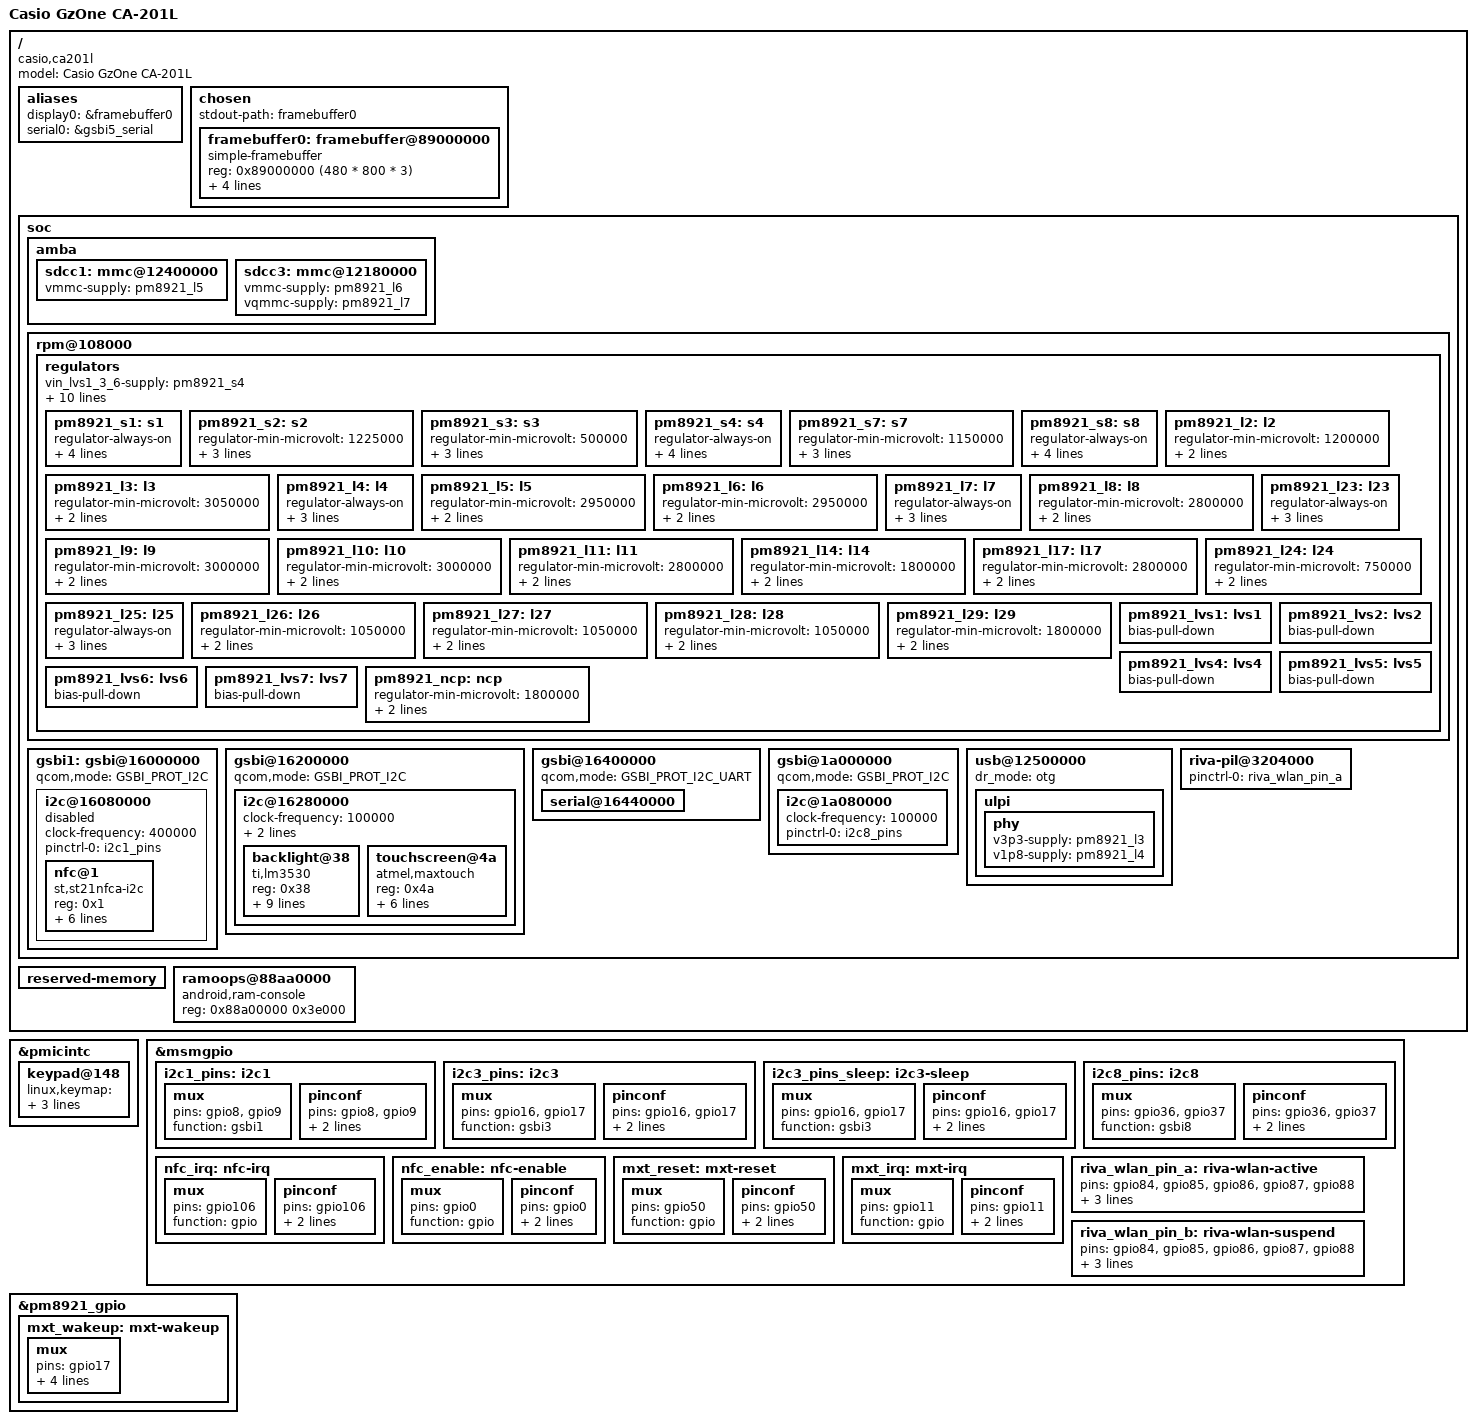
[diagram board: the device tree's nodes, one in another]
// SPDX-License-Identifier: GPL-2.0
#include <dt-bindings/input/input.h>
#include <dt-bindings/input/atmel-maxtouch.h>
#include <dt-bindings/gpio/gpio.h>
#include <dt-bindings/pinctrl/qcom,pmic-gpio.h>

#include "qcom-msm8960.dtsi"

/ {
	model = "Casio GzOne CA-201L";
	compatible = "casio,ca201l", "qcom,msm8960";

	aliases {
		display0 = &framebuffer0;
		serial0 = &gsbi5_serial;
	};

	chosen {
		stdout-path = "framebuffer0";

		#address-cells = <1>;
		#size-cells = <1>;
		ranges;

		framebuffer0: framebuffer@89000000 {
			compatible = "simple-framebuffer";
			reg = <0x89000000 (480 * 800 * 3)>;
			width = <480>;
			height = <800>;
			stride = <(480 * 3)>;
			//format = "b8g8r8";
			format = "r8g8b8";
		};
	};


	soc {
		amba {
		 	/* eMMC */
			sdcc1: mmc@12400000 {
				status = "okay";
				vmmc-supply = <&pm8921_l5>;
			};

		 	/* External micro SD card */
			sdcc3: mmc@12180000 {
				status = "okay";
				vmmc-supply = <&pm8921_l6>;
				vqmmc-supply = <&pm8921_l7>;
			};
		};

		rpm@108000 {
			regulators {
				vin_lvs1_3_6-supply = <&pm8921_s4>;
				vin_lvs2-supply = <&pm8921_s1>;
				vin_lvs4_5_7-supply = <&pm8921_s4>;
				vdd_ncp-supply = <&pm8921_l6>;
				vdd_l1_l2_l12_l18-supply = <&pm8921_s4>;
				vdd_l21_l23_l29-supply = <&pm8921_s8>;
				vdd_l24-supply = <&pm8921_s1>;
				vdd_l25-supply = <&pm8921_s1>;
				vdd_l26-supply = <&pm8921_s7>;
				vdd_l27-supply = <&pm8921_s7>;
				vdd_l28-supply = <&pm8921_s7>;

				/* Buck SMPS */
				/* lvs2 supply */
				pm8921_s1: s1 {
					regulator-always-on;
					regulator-min-microvolt = <1225000>;
					regulator-max-microvolt = <1225000>;
					qcom,switch-mode-frequency = <3200000>;
					bias-pull-down;
				};

				/* s2: iris_vddrfa (wcnss_wlan.0) */
				/* changed-min-microvolt -> 1225000 */
				/* changed-max-microvolt -> 1225000 */
				pm8921_s2: s2 {
					regulator-min-microvolt = <1225000>;
					regulator-max-microvolt = <1225000>;
					qcom,switch-mode-frequency = <1600000>;
					bias-pull-down;
				};

				/* s3: hsusb_vddcx (msm_otg), riva_vddcx (wcnss_wlan.0),
				   hsic_vddcx (msm_hsic_host) */
				pm8921_s3: s3 {
					regulator-min-microvolt = <500000>;
					regulator-max-microvolt = <1150000>;
					qcom,switch-mode-frequency = <4800000>;
					bias-pull-down;
				};

				/* s4: sdc_vdd_io (msm_sdcc.1), sdc_vdd (msm_sdcc.2),
				   sdc_vdd_io (msm_sdcc.4), riva_vddpx (wcnss_wlan.0),
				   hdmi_vcc (hdmi_msm.0), vddio_cdc, cdc_vdd_cp, cdc_vdda_tx,
				   cdc_vdda_rx (tabla-slim), vddio_cdc, cdc_vdd_cp,
				   cdc_vdda_tx, cdc_vdda_rx (tabla2x-slim), vcc_i2c (3-005b),
				   ext_hub_vddio (msm_hsic_host), vcc_i2c (10-0048) */
				pm8921_s4: s4 {
					regulator-always-on;
					regulator-min-microvolt = <1800000>;
					regulator-max-microvolt = <1800000>;
					qcom,switch-mode-frequency = <1600000>;
					bias-pull-down;
				};
			
				/* s5: krait0 */

				/* s6: krait1 */

				/* l28 supply */
				pm8921_s7: s7 {
					regulator-min-microvolt = <1150000>;
					regulator-max-microvolt = <1150000>;
					qcom,switch-mode-frequency = <3200000>;
					bias-pull-down;
				};

				/* l21, l23, l29 supply */
				pm8921_s8: s8 {
					regulator-always-on;
					regulator-min-microvolt = <2050000>;
					regulator-max-microvolt = <2050000>;
					qcom,switch-mode-frequency = <1600000>;
					bias-pull-down;
				};

				/* PMOS LDO */
				/* No consumers defined in downstream kernel */
				// pm8921_l1: l1 {
				// 	regulator-always-on;
				// 	regulator-min-microvolt = <1050000>;
				// 	regulator-max-microvolt = <1050000>;
				// 	bias-pull-down;
				// };

				/* l2: dsi_vdda (mipi_dsi.1), mipi_csi_vdd (msm_csid.[012]) */
				pm8921_l2: l2 {
					regulator-min-microvolt = <1200000>;
					regulator-max-microvolt = <1200000>;
					bias-pull-down;
				};

				/* l3: HSUSB_3p3 (msm_otg), voltage from drivers */
				/* changed-min-microvolt -> 3050000 */
				/* changed-max-microvolt -> 3300000 */
				pm8921_l3: l3 {
					regulator-min-microvolt = <3050000>;
					regulator-max-microvolt = <3300000>;
					bias-pull-down;
				};

				/* l4: HSUSB_1p8 (msm_otg), iris_vddxo (wcnss_wlan.0) */
				pm8921_l4: l4 {
					regulator-always-on;
					regulator-min-microvolt = <1800000>;
					regulator-max-microvolt = <1800000>;
					bias-pull-down;
				};

				/* l5: sdc_vdd (msm_sdcc.1) */
				pm8921_l5: l5 {
					regulator-min-microvolt = <2950000>;
					regulator-max-microvolt = <2950000>;
					bias-pull-down;
				};

				/* l6: sdc_vdd (msm_sdcc.3) */
				pm8921_l6: l6 {
					regulator-min-microvolt = <2950000>;
					regulator-max-microvolt = <2950000>;
					bias-pull-down;
				};

				/* l7: sdc_vdd_io (msm_sdcc.3) */
				pm8921_l7: l7 {
					regulator-always-on;
					regulator-min-microvolt = <1850000>;
					regulator-max-microvolt = <2950000>;
					bias-pull-down;
				};

				/* l8: dsi_vdc (mipi_dsi.1) */
				/* changed-max-microvolt -> 2800000 */
				pm8921_l8: l8 {
					regulator-min-microvolt = <2800000>;
					regulator-max-microvolt = <2800000>;
					bias-pull-down;
				};

				/* l9: vdd (3-0024), vdd_ana (3-004a), sensor_vdd (msm_dsps) */
				pm8921_l9: l9 {
					regulator-min-microvolt = <3000000>;
					regulator-max-microvolt = <3000000>;
					bias-pull-down;
				};

				/* l10: iris_vddpa (wcnss_wlan.0) */
				pm8921_l10: l10 {
					regulator-min-microvolt = <3000000>;
					regulator-max-microvolt = <3000000>;
					bias-pull-down;
				};

				/* l11: cam_vana (4-003c, 4-001a, 4-006c, 4-0048, 4-0020, 4-0034, 4-0036) */
				/* changed-min-microvolt -> 2800000 */
				/* changed-max-microvolt -> 2800000 */
				pm8921_l11: l11 {
					regulator-min-microvolt = <2800000>;
					regulator-max-microvolt = <2800000>;
					bias-pull-down;
				};

				/* No consumers defined in downstream kernel */
				// pm8921_l12: l12 {
				// 	regulator-min-microvolt = <1200000>;
				// 	regulator-max-microvolt = <1200000>;
				// 	bias-pull-down;
				// };

				/* l14: pa_therm (pm8xxx-adc) */
				pm8921_l14: l14 {
					regulator-min-microvolt = <1800000>;
					regulator-max-microvolt = <1800000>;
					bias-pull-down;
				};

				/* No consumers defined in downstream kernel */
				// pm8921_l15: l15 {
				// 	regulator-min-microvolt = <1800000>;
				// 	regulator-max-microvolt = <2950000>;
				// 	bias-pull-down;
				// };

				/* No consumers defined in downstream kernel */
				// pm8921_l16: l16 {
				// 	regulator-min-microvolt = <2800000>;
				// 	regulator-max-microvolt = <2800000>;
				// 	bias-pull-down;
				// };

				/* l17: cam_vdig (4-0036, 4-003c) */
				/* changed-min-microvolt -> 2800000 */
				/* changed-max-microvolt -> 2800000 */
				pm8921_l17: l17 {
					regulator-min-microvolt = <2800000>;
					regulator-max-microvolt = <2800000>;
					bias-pull-down;
				};

				/* No consumers defined in downstream kernel */
				// pm8921_l18: l18 {
				// 	regulator-min-microvolt = <1300000>;
				// 	regulator-max-microvolt = <1300000>;
				// 	bias-pull-down;
				// };

				/* No consumers defined in downstream kernel */
				// pm8921_l21: l21 {
				// 	regulator-min-microvolt = <1900000>;
				// 	regulator-max-microvolt = <1900000>;
				// 	bias-pull-down;
				// };

				/* No consumers defined in downstream kernel */
				// pm8921_l22: l22 {
				// 	regulator-min-microvolt = <2750000>;
				// 	regulator-max-microvolt = <2750000>;
				// 	bias-pull-down;
				// };

				/* l23: dsi_vddio (mipi_dsi.1), hdmi_avdd (hdmi_msm.0),
				   hdmi_pll_fs (mdp.0), pll_vdd (pil_riva, pil_qdsp6v4.[12]) */
				pm8921_l23: l23 {
					regulator-always-on;
					regulator-min-microvolt = <1800000>;
					regulator-max-microvolt = <1800000>;
					bias-pull-down;
				};

				/* l24: riva_vddmx (wcnss_wlan.0) */
				pm8921_l24: l24 {
					regulator-min-microvolt = <750000>;
					regulator-max-microvolt = <1150000>;
					bias-pull-down;
				};

				/* l25:vddd_cdc_d, cdc_vdda_a_1p2v (tabla-slim),
				   vddd_cdc_d, cdc_vdda_a_1p2v (tabla2x-slim) */
				pm8921_l25: l25 {
					regulator-always-on;
					regulator-min-microvolt = <1250000>;
					regulator-max-microvolt = <1250000>;
					bias-pull-down;
				};

				/* l26: core_vdd (pil_qdsp6v4.0) */
				pm8921_l26: l26 {
					regulator-min-microvolt = <1050000>;
					regulator-max-microvolt = <1050000>;
					bias-pull-down;
				};

				/* l27: core_vdd (pil_qdsp6v4.2) */
				pm8921_l27: l27 {
					regulator-min-microvolt = <1050000>;
					regulator-max-microvolt = <1050000>;
					bias-pull-down;
				};

				/* l28: core_vdd (pil_qdsp6v4.1) */
				pm8921_l28: l28 {
					regulator-min-microvolt = <1050000>;
					regulator-max-microvolt = <1050000>;
					bias-pull-down;
				};

				/* l29: touch_io */
				/* changed-min-microvolt -> 1800000 */
				/* changed-max-microvolt -> 1800000 */
				pm8921_l29: l29 {
					regulator-min-microvolt = <1800000>;
					regulator-max-microvolt = <1800000>;
					bias-pull-down;
				};

				/* Low Voltage Switch */
				/* lvs1: iris_vddio (wcnss_wlan.0) */
				pm8921_lvs1: lvs1 {
					bias-pull-down;
				};

				/* lvs2: iris_vdddig (wcnss_wlan.0) */
				pm8921_lvs2: lvs2 {
					bias-pull-down;
				};

				/* No consumers defined in downstream kernel */
				// pm8921_lvs3: lvs3 {
				// 	bias-pull-down;
				// };

				/* lvs4: vcc_i2c (3-0024, 3-004a), sensor_vddio (msm_dsps) */
				pm8921_lvs4: lvs4 {
					bias-pull-down;
				};

				/* lvs5: cam_vio (4-003c, 4-001a, 4-006c, 4-0048, 4-0020, 4-0036) */
				pm8921_lvs5: lvs5 {
					bias-pull-down;
				};

				/* lvs6: vdd_io (spi0.0) */
				/* No SPI devices are defined */
				pm8921_lvs6: lvs6 {
					bias-pull-down;
				};

				/* No consumers defined in downstream kernel */
				pm8921_lvs7: lvs7 {
					bias-pull-down;
				};

				/* No consumers defined in downstream kernel */
				pm8921_ncp: ncp {
					regulator-min-microvolt = <1800000>;
					regulator-max-microvolt = <1800000>;
					qcom,switch-mode-frequency = <1600000>;
				};
			};
		};

		/* gsbi1: i2c - st21nfca, GPIO: 8, 9, 106 (ST21NFCA_WAKEUP) */
		gsbi1: gsbi@16000000 {
			status = "okay";
			qcom,mode = <GSBI_PROT_I2C>;

			i2c@16080000 {
				status = "disabled";
				clock-frequency = <400000>;
				pinctrl-0 = <&i2c1_pins>;
				pinctrl-names = "default";

				/* 1-0001: st21nfca */
				/* st21nfca_probe : IRQ GPIO is 106
				   st21nfca_probe : ENA GPIO is 0
				   st21nfca_probe : IRQ_TYPE is 2, active_polarity is 0
				*/
				nfc@1 {
					compatible = "st,st21nfca-i2c";
					reg = <0x1>;

					pinctrl-names = "default";
					pinctrl-0 = <&nfc_irq>, <&nfc_enable>;
					interrupt-parent = <&msmgpio>;
					interrupts = <106 IRQ_TYPE_EDGE_FALLING>;
					enable-gpios = <&msmgpio 0 GPIO_ACTIVE_HIGH>;

					ese-present;
					uicc-present;
				};
			};
		};

		/* gsbi3: i2c - mxt224e, backlight (rev3, rev >= 8), GPIO: 16 (SDA), 17 (SCL) */
		gsbi@16200000 {
			status = "okay";
			qcom,mode = <GSBI_PROT_I2C>;

			i2c@16280000 {
				status = "okay";
				clock-frequency = <100000>;
				pinctrl-0 = <&i2c3_pins>;
				pinctrl-1 = <&i2c3_pins_sleep>;
				pinctrl-names = "default", "sleep";

				/* 3-0038: lm3530 */
				backlight@38 {
					status = "okay";
					compatible = "ti,lm3530";
					reg = <0x38>;

					enable-gpios = <&pm8921_gpio 24 GPIO_ACTIVE_HIGH>;
					default-brightness = /bits/ 8 <0x33>;
					max-brightness = /bits/ 8 <0x7f>;
					ramp-up-ms = <128>;
					ramp-down-ms = <128>;
					ti,current-limit = /bits/ 8 <0x05>; // 22.5 mA, bit 4 to 2 of 0x10
					ti,led-mode = /bits/ 8 <0x00>; /* Manual mode */
					ti,linear-mapping-mode = /bits/ 8 <1>; /* Linear map */
					ti,no-regulator;
				};

				/* 3-004a: mXT224E */
				/* power on: GPIO 50 -> 1, power off: GPIO 50 -> 0
				   TOUCH_RESET_GPIO 50 -> direction output, 1
				   MXT224E_TS_GPIO_IRQ 11 -> direction input
				   MXT224E_TS_VDD 17 -> PM8921_GPIO_PM_TO_SYS
				*/
				touchscreen@4a {
					compatible = "atmel,maxtouch";
					reg = <0x4a>;

					pinctrl-names = "default";
					pinctrl-0 = <&mxt_irq>, <&mxt_reset>, <&mxt_wakeup>;
					interrupt-parent = <&msmgpio>;
					interrupts = <11 IRQ_TYPE_LEVEL_LOW>;
					reset-gpios = <&msmgpio 50 GPIO_ACTIVE_LOW>;
					atmel,wakeup-method = <ATMEL_MXT_WAKEUP_GPIO>;
					wake-gpios = <&pm8921_gpio 17 GPIO_ACTIVE_HIGH>;
				};
			};
		};

		/* gsbi4: i2c - camera main, camera sub */
		// mt9m113, mt9e013 - no drivers
		// gsbi@16300000 {
		// 	status = "okay";
		// 	qcom,mode = <GSBI_PROT_I2C>;

		// 	i2c@16380000 {
		// 		status = "okay";
		// 		clock-frequency = <360000>;
		// 		pinctrl-0 = <&i2c4_pins>;
		// 		pinctrl-names = "default";
		// 	};
		// };

		/* gsbi5: uart (GPIO: 22, 23, 24, 25) */
		gsbi@16400000 {
			status = "okay";
			qcom,mode = <GSBI_PROT_I2C_UART>;
			serial@16440000 {
				status = "okay";
			};
		};

		/* gsbi8: i2c - yda160, es310 (GPIO: 36, 37) */
		// es310, yda160 - no drivers
		gsbi@1a000000 {
			status = "okay";
			qcom,mode = <GSBI_PROT_I2C>;

			i2c@1a080000 {
				status = "okay";
				clock-frequency = <100000>;
				pinctrl-0 = <&i2c8_pins>;
				pinctrl-names = "default";
			};
		};

		usb@12500000 {
			status = "okay";
			dr_mode = "otg";

			ulpi {
				phy {
					v3p3-supply = <&pm8921_l3>;
					v1p8-supply = <&pm8921_l4>;
				};
			};
		};

		riva-pil@3204000 {
			status = "okay";

			pinctrl-names = "default";
			pinctrl-0 = <&riva_wlan_pin_a>; //, <&riva_bt_pin_a>, <&riva_fm_pin_a>;
		};
	};

	reserved-memory {
		#address-cells = <1>;
		#size-cells = <1>;
		ranges;

		// framebuffer_region@89000000 {
		// 	reg = <0x89000000 (480 * 800 * 3)>;
		// 	no-map;
		// };
	};

	ramoops@88aa0000 {
		// compatible = "ramoops";
		compatible = "android,ram-console";
		reg = <0x88a00000 0x3e000>;
		// console-size = <0x3e000>;
		// record-size = <0x3e000>;
		// ftrace-size = <0x0>;
		// pmsg-size = <0x3e000>;
		// ecc-size = <0x10>;
	};

};

&pmicintc {
	keypad@148 {
		// KEY_TACTILE: only existing in this device
		linux,keymap = <
			MATRIX_KEY(0, 0, KEY_HOME)
			MATRIX_KEY(0, 1, KEY_VOLUMEUP)
			MATRIX_KEY(0, 2, KEY_VOLUMEDOWN)
			>;
		keypad,num-rows = <1>;
		keypad,num-columns = <5>;
	};
};

&msmgpio {
	i2c1_pins: i2c1 {
		mux {
			pins = "gpio8", "gpio9";
			function = "gsbi1";
		};

		pinconf {
			pins = "gpio8", "gpio9";
			drive-strength = <8>;
			bias-disable;
		};
	};

	i2c3_pins: i2c3 {
		mux {
			pins = "gpio16", "gpio17";
			function = "gsbi3";
		};

		pinconf {
			pins = "gpio16", "gpio17";
			drive-strength = <8>;
			bias-disable;
		};
	};

	i2c3_pins_sleep: i2c3-sleep {
		mux {
			pins = "gpio16", "gpio17";
			function = "gsbi3";
		};

		pinconf {
			pins = "gpio16", "gpio17";
			drive-strength = <2>;
			bias-disable;
		};
	};

	i2c8_pins: i2c8 {
		mux {
			pins = "gpio36", "gpio37";
			function = "gsbi8";
		};

		pinconf {
			pins = "gpio36", "gpio37";
			drive-strength = <8>;
			bias-disable;
		};
	};

	nfc_irq: nfc-irq {
		mux {
			pins = "gpio106";
			function = "gpio";
		};

		pinconf {
			pins = "gpio106";
			drive-strengh = <2>;
			bias-disable;
		};
	};

	nfc_enable: nfc-enable {
		mux {
			pins = "gpio0";
			function = "gpio";
		};

		pinconf {
			pins = "gpio0";
			drive-strengh = <2>;
			bias-disable;
		};
	};

	mxt_reset: mxt-reset {
		mux {
			pins = "gpio50";
			function = "gpio";
		};

		pinconf {
			pins = "gpio50";
			drive-strength = <6>;
			bias-pull-up;
		};
	};

	mxt_irq: mxt-irq {
		mux {
			pins = "gpio11";
			function = "gpio";
		};

		pinconf {
			pins = "gpio11";
			drive-strength = <8>;
			bias-pull-up;
		};
	};

	// riva_fm_pin_a: riva-fm-active {
	// 	pins = "gpio14", "gpio15";
	// 	function = "riva_fm";
	// };

	// riva_bt_pin_a: riva-bt-active {
	// 	pins = "gpio16", "gpio17";
	// 	function = "riva_bt";
	// };

	riva_wlan_pin_a: riva-wlan-active {
		pins = "gpio84", "gpio85", "gpio86", "gpio87", "gpio88";
		function = "wlan";

		drive-strength = <6>;
		bias-pull-down;
	};

	riva_wlan_pin_b: riva-wlan-suspend {
		pins = "gpio84", "gpio85", "gpio86", "gpio87", "gpio88";
		function = "gpio";

		drive-strength = <2>;
		bias-pull-up;
	};
};

&pm8921_gpio {
	mxt_wakeup: mxt-wakeup {
		mux {
			pins = "gpio17";
			function = "normal";
			bias-disable;
			qcom,drive-strength = <PMIC_GPIO_STRENGTH_HIGH>;
			power-source = <PM8921_GPIO_S4>;
		};
	};
};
